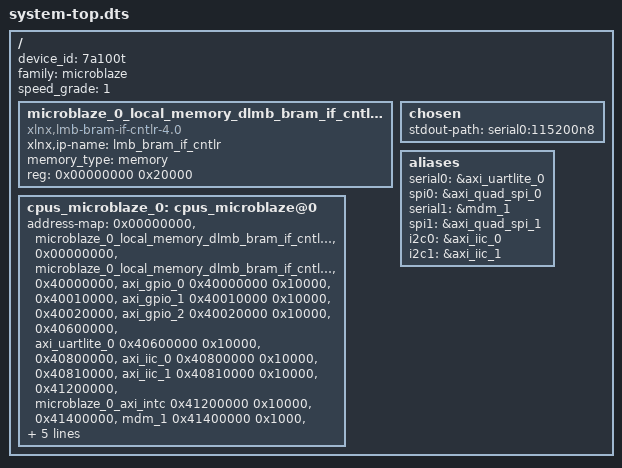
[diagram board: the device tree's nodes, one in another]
/dts-v1/;
#include "pl.dtsi"
/ {
	device_id = "7a100t";
	#address-cells = <1>;
	#size-cells = <1>;
	family = "microblaze";
	speed_grade = "1";
	microblaze_0_local_memory_dlmb_bram_if_cntlr_memory: memory@0 {
		compatible = "xlnx,lmb-bram-if-cntlr-4.0";
		xlnx,ip-name = "lmb_bram_if_cntlr";
		device_type = "memory";
		memory_type = "memory";
		reg = <0x00000000 0x20000>;
	};
	chosen {
		stdout-path = "serial0:115200n8";
	};
	aliases {
		serial0 = &axi_uartlite_0;
		spi0 = &axi_quad_spi_0;
		serial1 = &mdm_1;
		spi1 = &axi_quad_spi_1;
		i2c0 = &axi_iic_0;
		i2c1 = &axi_iic_1;
	};
	cpus_microblaze_0: cpus_microblaze@0 {
		address-map = <0x00000000 &microblaze_0_local_memory_dlmb_bram_if_cntlr_memory 0x00000000 0x20000>, 
			      <0x00000000 &microblaze_0_local_memory_dlmb_bram_if_cntlr 0x00000000 0x20000>, 
			      <0x40000000 &axi_gpio_0 0x40000000 0x10000>, 
			      <0x40010000 &axi_gpio_1 0x40010000 0x10000>, 
			      <0x40020000 &axi_gpio_2 0x40020000 0x10000>, 
			      <0x40600000 &axi_uartlite_0 0x40600000 0x10000>, 
			      <0x40800000 &axi_iic_0 0x40800000 0x10000>, 
			      <0x40810000 &axi_iic_1 0x40810000 0x10000>, 
			      <0x41200000 &microblaze_0_axi_intc 0x41200000 0x10000>, 
			      <0x41400000 &mdm_1 0x41400000 0x1000>, 
			      <0x41c00000 &axi_timer_0 0x41c00000 0x10000>, 
			      <0x44a00000 &axi_quad_spi_0 0x44a00000 0x10000>, 
			      <0x44a10000 &axi_quad_spi_1 0x44a10000 0x10000>;
		#ranges-address-cells = <0x1>;
		#ranges-size-cells = <0x1>;
	};
};
